# STM32H7A3ZIT6Q register map
File version: 1.0
Registers are 32-bit, access not given, reset 0x0 unless marked. A register's access mark holds for its fields unless they carry their own. Offsets are from the block's base; [hi:lo] are bit positions.

## I2C1
Base 0x40005400
Same registers: I2C2 0x40005800, I2C3 0x40005C00, I2C4 0x58001C00
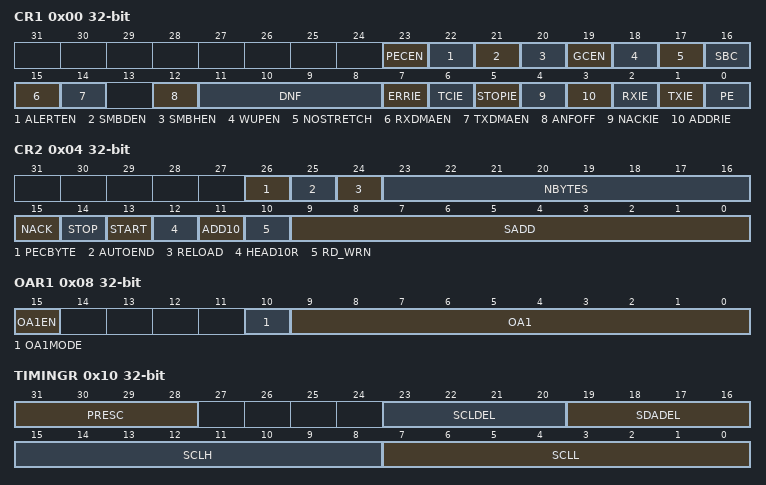
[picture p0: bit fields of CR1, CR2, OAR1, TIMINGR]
0x00 CR1
  [23] PECEN, [22] ALERTEN, [21] SMBDEN, [20] SMBHEN, [19] GCEN, [18] WUPEN, [17] NOSTRETCH, [16] SBC, [15] RXDMAEN, [14] TXDMAEN, [12] ANFOFF, [11:8] DNF, [7] ERRIE, [6] TCIE, [5] STOPIE, [4] NACKIE, [3] ADDRIE, [2] RXIE, [1] TXIE, [0] PE
0x04 CR2
  [26] PECBYTE, [25] AUTOEND, [24] RELOAD, [23:16] NBYTES, [15] NACK, [14] STOP, [13] START, [12] HEAD10R, [11] ADD10, [10] RD_WRN, [9:0] SADD
0x08 OAR1
  [15] OA1EN, [10] OA1MODE, [9:0] OA1
0x0C OAR2
  [15] OA2EN, [10] OA2MASK04, [10:9] OA2MASK06, [10:8] OA2MSK, [7:1] OA2
0x10 TIMINGR
  [31:28] PRESC, [23:20] SCLDEL, [19:16] SDADEL, [15:8] SCLH, [7:0] SCLL
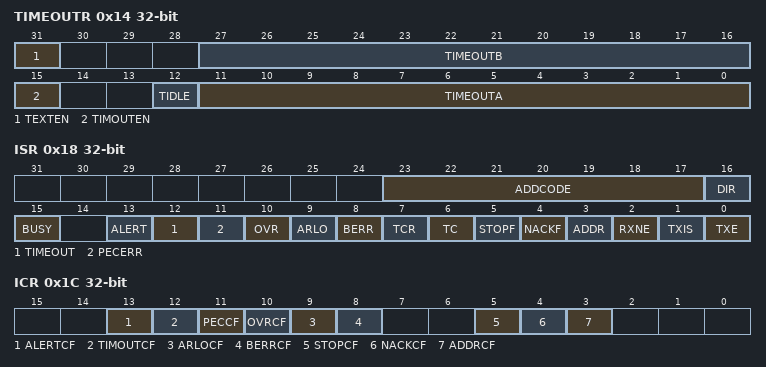
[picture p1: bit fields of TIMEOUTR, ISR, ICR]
0x14 TIMEOUTR
  [31] TEXTEN, [27:16] TIMEOUTB, [15] TIMOUTEN, [12] TIDLE, [11:0] TIMEOUTA
0x18 ISR
  [23:17] ADDCODE, [16] DIR, [15] BUSY, [13] ALERT, [12] TIMEOUT, [11] PECERR, [10] OVR, [9] ARLO, [8] BERR, [7] TCR, [6] TC, [5] STOPF, [4] NACKF, [3] ADDR, [2] RXNE, [1] TXIS, [0] TXE
0x1C ICR
  [13] ALERTCF, [12] TIMOUTCF, [11] PECCF, [10] OVRCF, [9] ARLOCF, [8] BERRCF, [5] STOPCF, [4] NACKCF, [3] ADDRCF
0x20 PECR
  [7:0] PEC
0x24 RXDR
  [7:0] RXDATA
0x28 TXDR
  [7:0] TXDATA

## CEC
Base 0x40006C00
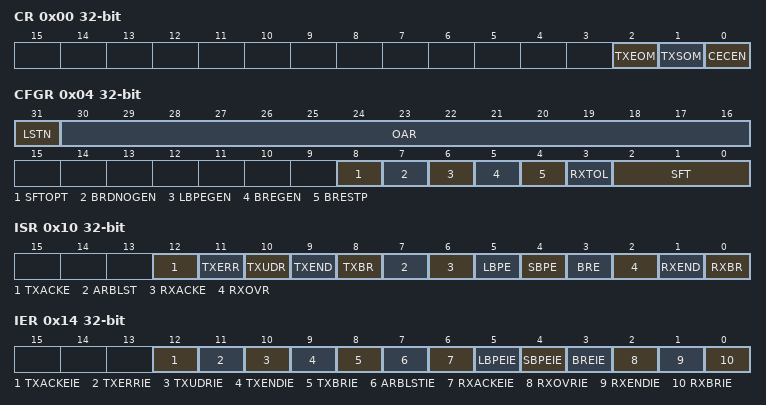
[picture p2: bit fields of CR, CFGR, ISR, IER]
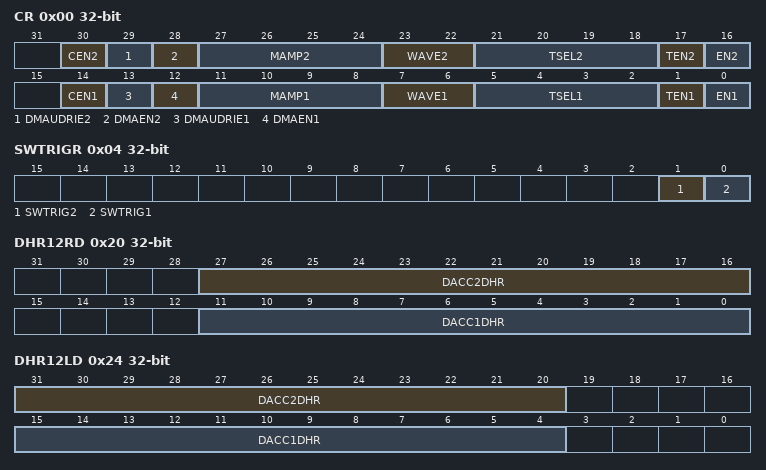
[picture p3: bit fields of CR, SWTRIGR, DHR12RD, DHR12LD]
0x00 CR
  [2] TXEOM, [1] TXSOM, [0] CECEN
0x04 CFGR
  [31] LSTN, [30:16] OAR, [8] SFTOPT, [7] BRDNOGEN, [6] LBPEGEN, [5] BREGEN, [4] BRESTP, [3] RXTOL, [2:0] SFT
0x08 TXDR
  [7:0] TXD
0x0C RXDR
  [7:0] RXD
0x10 ISR
  [12] TXACKE, [11] TXERR, [10] TXUDR, [9] TXEND, [8] TXBR, [7] ARBLST, [6] RXACKE, [5] LBPE, [4] SBPE, [3] BRE, [2] RXOVR, [1] RXEND, [0] RXBR
0x14 IER
  [12] TXACKEIE, [11] TXERRIE, [10] TXUDRIE, [9] TXENDIE, [8] TXBRIE, [7] ARBLSTIE, [6] RXACKEIE, [5] LBPEIE, [4] SBPEIE, [3] BREIE, [2] RXOVRIE, [1] RXENDIE, [0] RXBRIE

## DAC1
Base 0x40007400
Same registers: DAC2 0x58003400
0x00 CR
  [30] CEN2, [29] DMAUDRIE2, [28] DMAEN2, [27:24] MAMP2, [23:22] WAVE2, [21:18] TSEL2, [17] TEN2, [16] EN2, [14] CEN1, [13] DMAUDRIE1, [12] DMAEN1, [11:8] MAMP1, [7:6] WAVE1, [5:2] TSEL1, [1] TEN1, [0] EN1
0x04 SWTRIGR
  [1] SWTRIG2, [0] SWTRIG1
0x08 DHR12R1
  [11:0] DACC1DHR
0x0C DHR12L1
  [15:4] DACC1DHR
0x10 DHR8R1
  [7:0] DACC1DHR
0x14 DHR12R2
  [11:0] DACC2DHR
0x18 DHR12L2
  [15:4] DACC2DHR
0x1C DHR8R2
  [7:0] DACC2DHR
0x20 DHR12RD
  [27:16] DACC2DHR, [11:0] DACC1DHR
0x24 DHR12LD
  [31:20] DACC2DHR, [15:4] DACC1DHR
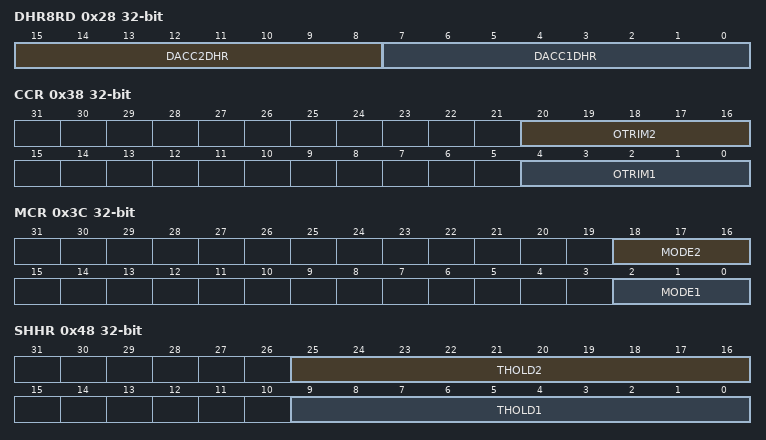
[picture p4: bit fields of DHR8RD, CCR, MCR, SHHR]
0x28 DHR8RD
  [15:8] DACC2DHR, [7:0] DACC1DHR
0x2C DOR1
  [11:0] DACC1DOR
0x30 DOR2
  [11:0] DACC2DOR
0x34 SR
  [31] BWST2, [30] CAL_FLAG2, [29] DMAUDR2, [29:15] BWST1, [14] CAL_FLAG1, [13] DMAUDR1
0x38 CCR
  [20:16] OTRIM2, [4:0] OTRIM1
0x3C MCR
  [18:16] MODE2, [2:0] MODE1
0x40 SHSR1
  [9:0] TSAMPLE1
0x44 SHSR2
  [9:0] TSAMPLE2
0x48 SHHR
  [25:16] THOLD2, [9:0] THOLD1
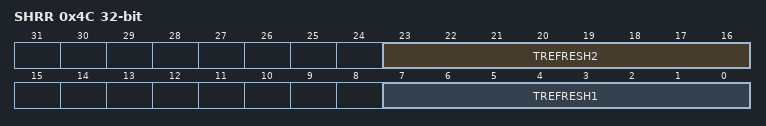
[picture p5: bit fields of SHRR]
0x4C SHRR
  [23:16] TREFRESH2, [7:0] TREFRESH1

## CRS
Base 0x40008400
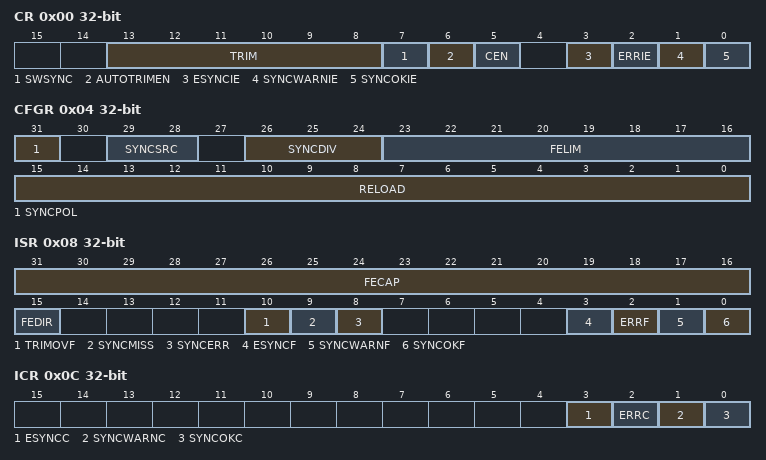
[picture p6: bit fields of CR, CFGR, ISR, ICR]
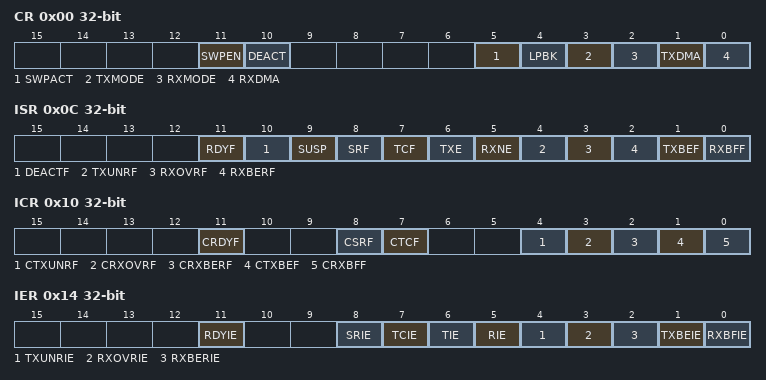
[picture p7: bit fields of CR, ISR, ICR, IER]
0x00 CR
  [13:8] TRIM, [7] SWSYNC, [6] AUTOTRIMEN, [5] CEN, [3] ESYNCIE, [2] ERRIE, [1] SYNCWARNIE, [0] SYNCOKIE
0x04 CFGR
  [31] SYNCPOL, [29:28] SYNCSRC, [26:24] SYNCDIV, [23:16] FELIM, [15:0] RELOAD
0x08 ISR
  [31:16] FECAP, [15] FEDIR, [10] TRIMOVF, [9] SYNCMISS, [8] SYNCERR, [3] ESYNCF, [2] ERRF, [1] SYNCWARNF, [0] SYNCOKF
0x0C ICR
  [3] ESYNCC, [2] ERRC, [1] SYNCWARNC, [0] SYNCOKC

## SWPMI1
Base 0x40008800
0x00 CR
  [11] SWPEN, [10] DEACT, [5] SWPACT, [4] LPBK, [3] TXMODE, [2] RXMODE, [1] TXDMA, [0] RXDMA
0x04 BRR
  [7:0] BR
0x0C ISR
  [11] RDYF, [10] DEACTF, [9] SUSP, [8] SRF, [7] TCF, [6] TXE, [5] RXNE, [4] TXUNRF, [3] RXOVRF, [2] RXBERF, [1] TXBEF, [0] RXBFF
0x10 ICR
  [11] CRDYF, [8] CSRF, [7] CTCF, [4] CTXUNRF, [3] CRXOVRF, [2] CRXBERF, [1] CTXBEF, [0] CRXBFF
0x14 IER
  [11] RDYIE, [8] SRIE, [7] TCIE, [6] TIE, [5] RIE, [4] TXUNRIE, [3] RXOVRIE, [2] RXBERIE, [1] TXBEIE, [0] RXBFIE
0x18 RFL
  [4:0] RFL
0x1C TDR
  [31:0] TD
0x20 RDR
  [31:0] RD
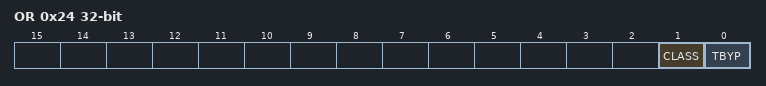
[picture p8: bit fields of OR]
0x24 OR
  [1] CLASS, [0] TBYP
